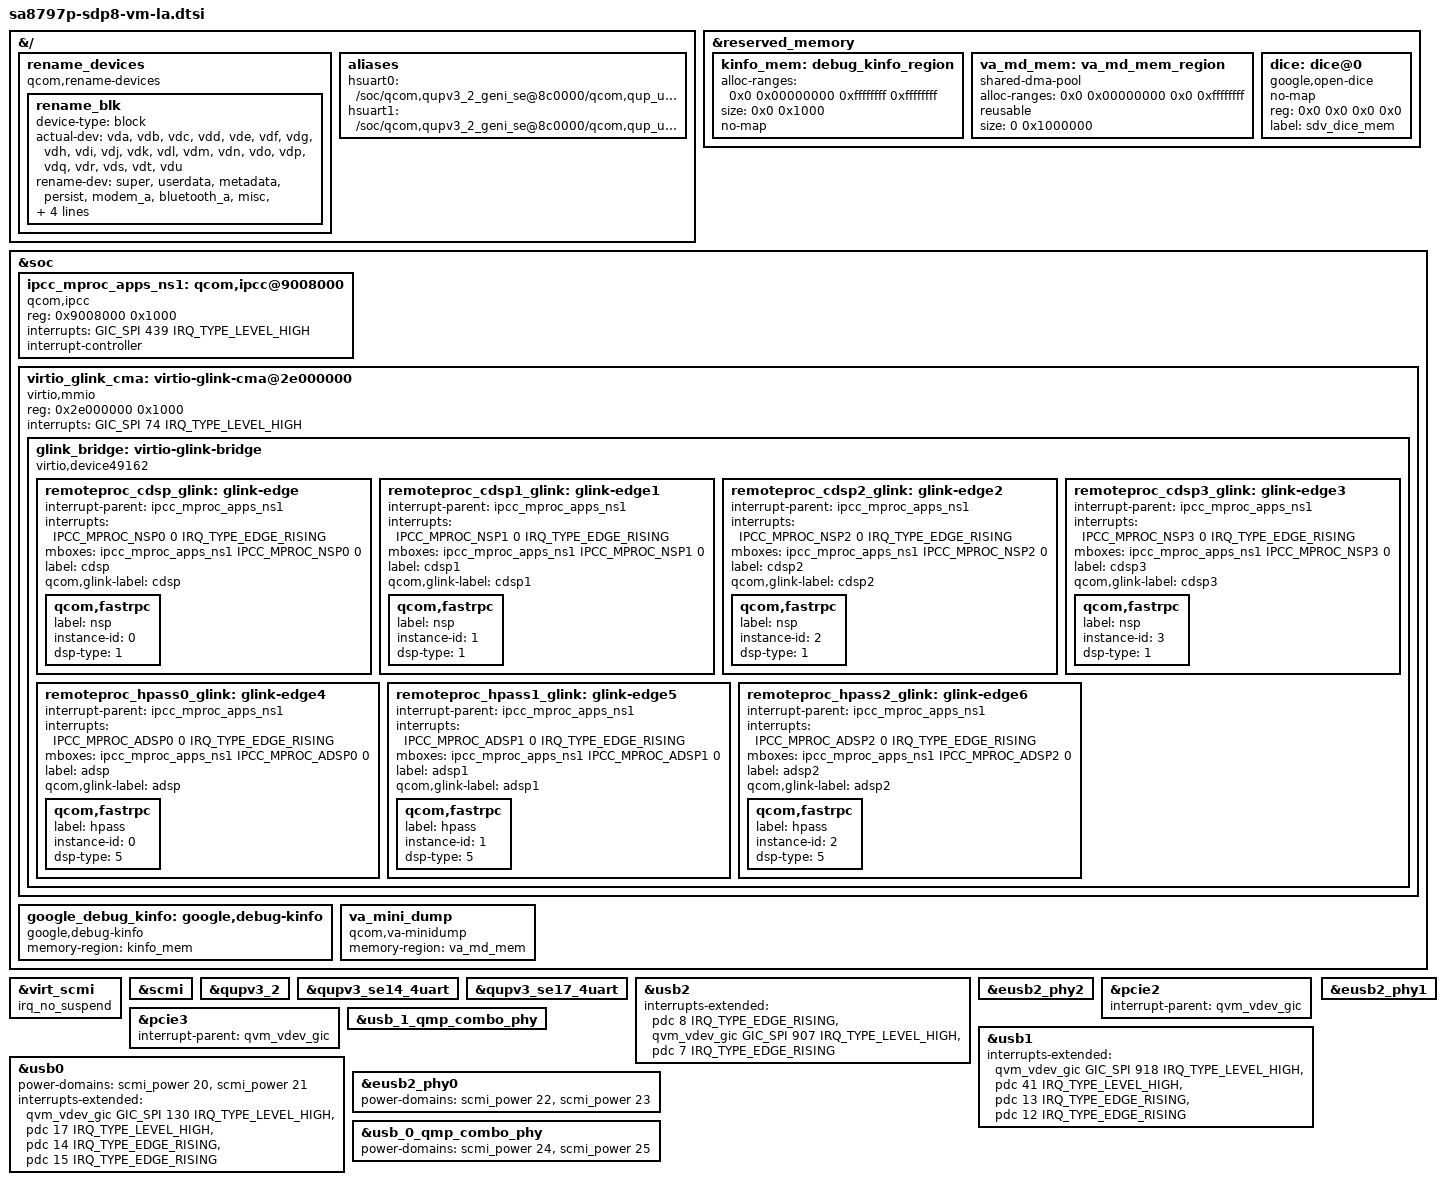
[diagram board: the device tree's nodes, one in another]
// SPDX-License-Identifier: BSD-3-Clause
/*
 * Copyright (c) Qualcomm Technologies, Inc. and/or its subsidiaries.
 */

#include <dt-bindings/mailbox/qcom-ipcc.h>
#include <dt-bindings/soc/qcom,ipcc.h>
#include <dt-bindings/mailbox/qcom-ipcc-sa8797p.h>

&{/} {
	rename_devices: rename_devices {
		compatible = "qcom,rename-devices";
		rename_blk: rename_blk {
			device-type = "block";
			actual-dev = "vda", "vdb", "vdc",
					"vdd", "vde", "vdf",
					"vdg", "vdh", "vdi",
					"vdj", "vdk", "vdl",
					"vdm", "vdn", "vdo",
					"vdp", "vdq", "vdr",
					"vds", "vdt", "vdu";
			rename-dev = "super", "userdata", "metadata",
					"persist", "modem_a","bluetooth_a",
					"misc", "vbmeta_a", "vbmeta_b",
					"boot_a", "dtbo_a", "dsp_a",
					"modem_b", "bluetooth_b", "boot_b",
					"dtbo_b", "dsp_b", "vendor_boot_b",
					"vendor_boot_a", "init_boot_b", "init_boot_a";
		};
	};
	aliases: aliases {
		hsuart0 = "/soc/qcom,qupv3_2_geni_se@8c0000/qcom,qup_uart@88c000";
		hsuart1 = "/soc/qcom,qupv3_2_geni_se@8c0000/qcom,qup_uart14@880000";
	};
};

&reserved_memory {
	kinfo_mem: debug_kinfo_region {
		alloc-ranges = <0x0 0x00000000 0xffffffff 0xffffffff>;
		size = <0x0 0x1000>;
		no-map;
	};

	va_md_mem: va_md_mem_region {
		compatible = "shared-dma-pool";
		alloc-ranges = <0x0 0x00000000 0x0 0xffffffff>;
		reusable;
		size = <0 0x1000000>;
	};

	dice: dice@0 {
		compatible = "google,open-dice";
		no-map;
		reg = <0x0 0x0 0x0 0x0>;
		label = "sdv_dice_mem";
	};
};

&soc {
	ipcc_mproc_apps_ns1: qcom,ipcc@9008000 {
		compatible = "qcom,ipcc";
		reg = <0x9008000 0x1000>;
		interrupts = <GIC_SPI 439 IRQ_TYPE_LEVEL_HIGH>;
		interrupt-controller;
		#interrupt-cells = <3>;
		#mbox-cells = <2>;
		status = "ok";
	};

	virtio_glink_cma: virtio-glink-cma@2e000000 {
		compatible = "virtio,mmio";
		reg = <0x2e000000 0x1000>;
		interrupts = <GIC_SPI 74 IRQ_TYPE_LEVEL_HIGH>;

		glink_bridge: virtio-glink-bridge {
			compatible = "virtio,device49162"; /* VIRTIO_ID: 0xC00A */

			remoteproc_cdsp_glink: glink-edge {
				interrupt-parent = <&ipcc_mproc_apps_ns1>;
				interrupts = <IPCC_MPROC_NSP0 0 IRQ_TYPE_EDGE_RISING>;
				mboxes = <&ipcc_mproc_apps_ns1 IPCC_MPROC_NSP0 0>;
				label = "cdsp";
				qcom,glink-label = "cdsp";
			};

			remoteproc_cdsp1_glink: glink-edge1 {
				interrupt-parent = <&ipcc_mproc_apps_ns1>;
				interrupts = <IPCC_MPROC_NSP1 0 IRQ_TYPE_EDGE_RISING>;
				mboxes = <&ipcc_mproc_apps_ns1 IPCC_MPROC_NSP1 0>;
				label = "cdsp1";
				qcom,glink-label = "cdsp1";
			};

			remoteproc_cdsp2_glink: glink-edge2 {
				interrupt-parent = <&ipcc_mproc_apps_ns1>;
				interrupts = <IPCC_MPROC_NSP2 0 IRQ_TYPE_EDGE_RISING>;
				mboxes = <&ipcc_mproc_apps_ns1 IPCC_MPROC_NSP2 0>;
				label = "cdsp2";
				qcom,glink-label = "cdsp2";
			};

			remoteproc_cdsp3_glink: glink-edge3 {
				interrupt-parent = <&ipcc_mproc_apps_ns1>;
				interrupts = <IPCC_MPROC_NSP3 0 IRQ_TYPE_EDGE_RISING>;
				mboxes = <&ipcc_mproc_apps_ns1 IPCC_MPROC_NSP3 0>;
				label = "cdsp3";
				qcom,glink-label = "cdsp3";
			};

			remoteproc_hpass0_glink: glink-edge4 {
				interrupt-parent = <&ipcc_mproc_apps_ns1>;
				interrupts = <IPCC_MPROC_ADSP0 0 IRQ_TYPE_EDGE_RISING>;
				mboxes = <&ipcc_mproc_apps_ns1 IPCC_MPROC_ADSP0 0>;
				label = "adsp";
				qcom,glink-label = "adsp";
			};

			remoteproc_hpass1_glink: glink-edge5 {
				interrupt-parent = <&ipcc_mproc_apps_ns1>;
				interrupts = <IPCC_MPROC_ADSP1 0 IRQ_TYPE_EDGE_RISING>;
				mboxes = <&ipcc_mproc_apps_ns1 IPCC_MPROC_ADSP1 0>;
				label = "adsp1";
				qcom,glink-label = "adsp1";
			};

			remoteproc_hpass2_glink: glink-edge6 {
				interrupt-parent = <&ipcc_mproc_apps_ns1>;
				interrupts = <IPCC_MPROC_ADSP2  0 IRQ_TYPE_EDGE_RISING>;
				mboxes = <&ipcc_mproc_apps_ns1 IPCC_MPROC_ADSP2 0>;
				label = "adsp2";
				qcom,glink-label = "adsp2";
			};
		};
	};

	google_debug_kinfo: google,debug-kinfo {
		compatible = "google,debug-kinfo";
		memory-region = <&kinfo_mem>;
	};

	va_mini_dump: va_mini_dump {
		compatible = "qcom,va-minidump";
		memory-region = <&va_md_mem>;
	};
};

&virt_scmi {
	irq_no_suspend;
	status = "ok";
};

&scmi {
	status = "ok";
};

&qupv3_2 {
	status = "ok";
};

&qupv3_se14_4uart {
	status = "ok";
};

&qupv3_se17_4uart {
	status = "ok";
};

&usb2 {
	interrupts-extended = <&pdc 8 IRQ_TYPE_EDGE_RISING>,
			<&qvm_vdev_gic GIC_SPI 907 IRQ_TYPE_LEVEL_HIGH>,
			<&pdc 7 IRQ_TYPE_EDGE_RISING>;
	status = "ok";
};

&eusb2_phy2 {
	status = "ok";
};

&pcie2 {
	interrupt-parent = <&qvm_vdev_gic>;
	status = "ok";
};

&pcie3 {
	interrupt-parent = <&qvm_vdev_gic>;
	status = "ok";
};

&usb1 {
	interrupts-extended = <&qvm_vdev_gic GIC_SPI 918 IRQ_TYPE_LEVEL_HIGH>,
			<&pdc 41 IRQ_TYPE_LEVEL_HIGH>,
			<&pdc 13 IRQ_TYPE_EDGE_RISING>,
			<&pdc 12 IRQ_TYPE_EDGE_RISING>;
	status = "ok";
};

&usb_1_qmp_combo_phy {
	status = "ok";
};

&eusb2_phy1 {
	status = "ok";
};

&usb0 {
	power-domains = <&scmi_power 20>, <&scmi_power 21>;
	interrupts-extended = <&qvm_vdev_gic GIC_SPI 130 IRQ_TYPE_LEVEL_HIGH>,
		<&pdc 17 IRQ_TYPE_LEVEL_HIGH>,
		<&pdc 14 IRQ_TYPE_EDGE_RISING>,
		<&pdc 15 IRQ_TYPE_EDGE_RISING>;
};

&eusb2_phy0 {
	power-domains = <&scmi_power 22>, <&scmi_power 23>;
};

&usb_0_qmp_combo_phy {
	power-domains = <&scmi_power 24>, <&scmi_power 25>;
};

&remoteproc_cdsp_glink {
	qcom,fastrpc {
		label = "nsp";
		instance-id = <0>;
		dsp-type = <1>;
	};
};

&remoteproc_cdsp1_glink {
	qcom,fastrpc {
		label = "nsp";
		instance-id = <1>;
		dsp-type = <1>;
	};
};

&remoteproc_cdsp2_glink {
	qcom,fastrpc {
		label = "nsp";
		instance-id = <2>;
		dsp-type = <1>;
	};
};

&remoteproc_cdsp3_glink {
	qcom,fastrpc {
		label = "nsp";
		instance-id = <3>;
		dsp-type = <1>;
	};
};

&remoteproc_hpass0_glink {
	qcom,fastrpc {
		label = "hpass";
		instance-id = <0>;
		dsp-type = <5>;
	};
};

&remoteproc_hpass1_glink {
	qcom,fastrpc {
		label = "hpass";
		instance-id = <1>;
		dsp-type = <5>;
	};
};

&remoteproc_hpass2_glink {
	qcom,fastrpc {
		label = "hpass";
		instance-id = <2>;
		dsp-type = <5>;
	};
};
